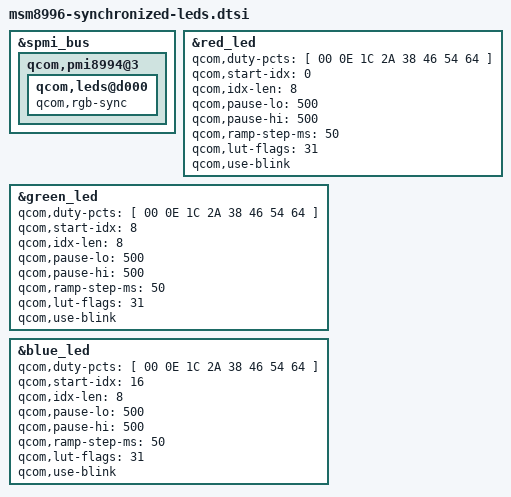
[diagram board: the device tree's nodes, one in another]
/* Copyright (c) 2017, The Linux Foundation. All rights reserved.
 *
 * This program is free software; you can redistribute it and/or modify
 * it under the terms of the GNU General Public License version 2 and
 * only version 2 as published by the Free Software Foundation.
 *
 * This program is distributed in the hope that it will be useful,
 * but WITHOUT ANY WARRANTY; without even the implied warranty of
 * MERCHANTABILITY or FITNESS FOR A PARTICULAR PURPOSE.  See the
 * GNU General Public License for more details.
 */

&spmi_bus {
	qcom,pmi8994@3 {
		qcom,leds@d000 {
			qcom,rgb-sync;
		};
	};
};

&red_led {
	/delete-property/ linux,default-trigger;
	qcom,duty-pcts = [ 00 0E 1C 2A 38 46 54 64 ];
	qcom,start-idx = <0>;
	qcom,idx-len = <8>;
	qcom,pause-lo = <500>;
	qcom,pause-hi = <500>;
	qcom,ramp-step-ms = <50>;
	qcom,lut-flags = <31>; /* loop, ramp up, reverse, pause hi, pause lo */
	qcom,use-blink;
};

&green_led {
	/delete-property/ linux,default-trigger;
	qcom,duty-pcts = [ 00 0E 1C 2A 38 46 54 64 ];
	qcom,start-idx = <8>;
	qcom,idx-len = <8>;
	qcom,pause-lo = <500>;
	qcom,pause-hi = <500>;
	qcom,ramp-step-ms = <50>;
	qcom,lut-flags = <31>; /* loop, ramp up, reverse, pause hi, pause lo */
	qcom,use-blink;
};

&blue_led {
	/delete-property/ linux,default-trigger;
	qcom,duty-pcts = [ 00 0E 1C 2A 38 46 54 64 ];
	qcom,start-idx = <16>;
	qcom,idx-len = <8>;
	qcom,pause-lo = <500>;
	qcom,pause-hi = <500>;
	qcom,ramp-step-ms = <50>;
	qcom,lut-flags = <31>; /* loop, ramp up, reverse, pause hi, pause lo */
	qcom,use-blink;
};
